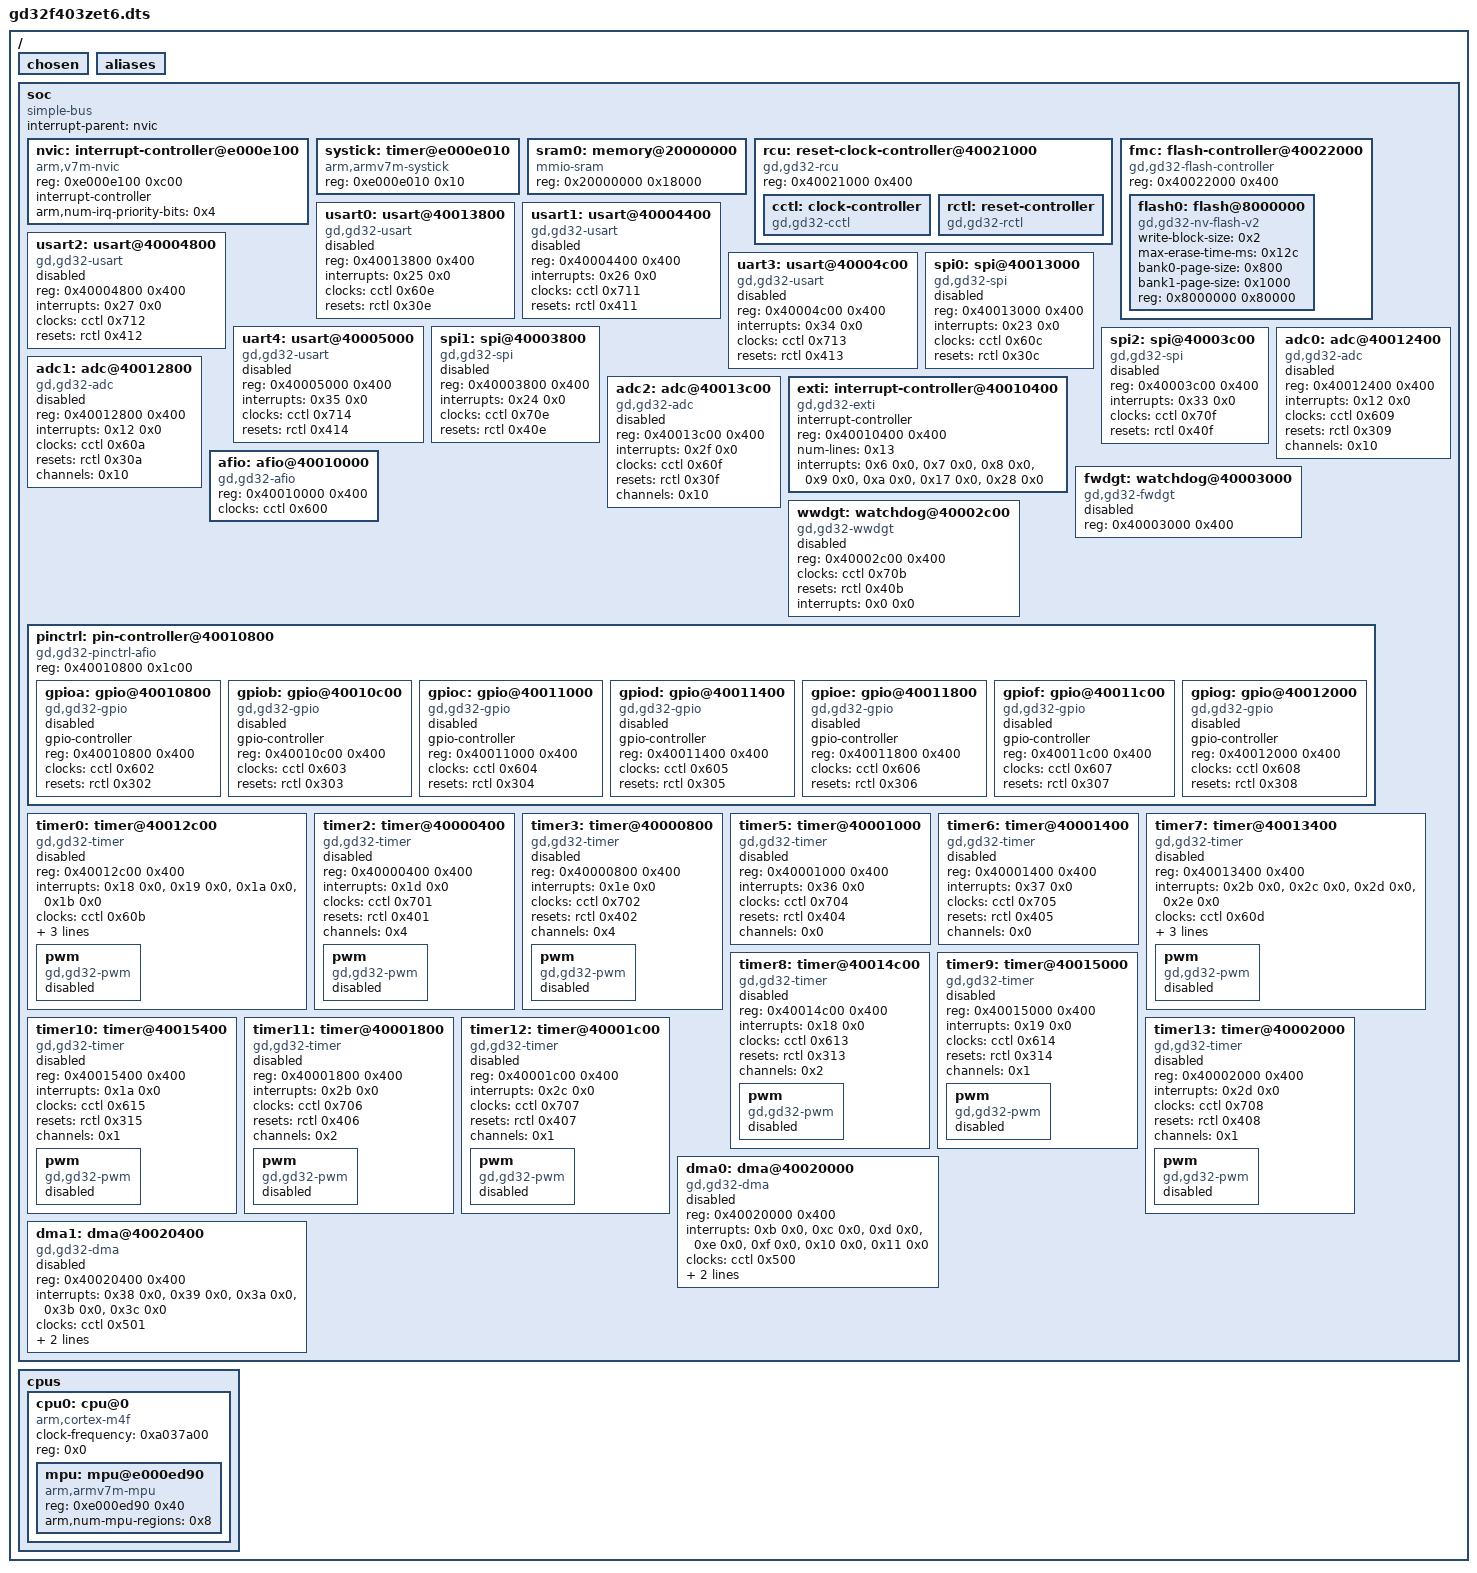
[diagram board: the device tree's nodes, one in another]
/dts-v1/;

/ {
	#address-cells = < 0x1 >;
	#size-cells = < 0x1 >;
	chosen {
	};
	aliases {
	};
	soc {
		#address-cells = < 0x1 >;
		#size-cells = < 0x1 >;
		compatible = "simple-bus";
		interrupt-parent = < &nvic >;
		ranges;
		nvic: interrupt-controller@e000e100 {
			#address-cells = < 0x1 >;
			compatible = "arm,v7m-nvic";
			reg = < 0xe000e100 0xc00 >;
			interrupt-controller;
			#interrupt-cells = < 0x2 >;
			arm,num-irq-priority-bits = < 0x4 >;
			phandle = < 0x1 >;
		};
		systick: timer@e000e010 {
			compatible = "arm,armv7m-systick";
			reg = < 0xe000e010 0x10 >;
		};
		sram0: memory@20000000 {
			compatible = "mmio-sram";
			reg = < 0x20000000 0x18000 >;
		};
		rcu: reset-clock-controller@40021000 {
			compatible = "gd,gd32-rcu";
			reg = < 0x40021000 0x400 >;
			status = "okay";
			cctl: clock-controller {
				compatible = "gd,gd32-cctl";
				#clock-cells = < 0x1 >;
				status = "okay";
				phandle = < 0x2 >;
			};
			rctl: reset-controller {
				compatible = "gd,gd32-rctl";
				#reset-cells = < 0x1 >;
				status = "okay";
				phandle = < 0x3 >;
			};
		};
		fmc: flash-controller@40022000 {
			compatible = "gd,gd32-flash-controller";
			reg = < 0x40022000 0x400 >;
			#address-cells = < 0x1 >;
			#size-cells = < 0x1 >;
			flash0: flash@8000000 {
				compatible = "gd,gd32-nv-flash-v2", "soc-nv-flash";
				write-block-size = < 0x2 >;
				max-erase-time-ms = < 0x12c >;
				bank0-page-size = < 0x800 >;
				bank1-page-size = < 0x1000 >;
				reg = < 0x8000000 0x80000 >;
			};
		};
		usart0: usart@40013800 {
			compatible = "gd,gd32-usart";
			reg = < 0x40013800 0x400 >;
			interrupts = < 0x25 0x0 >;
			clocks = < &cctl 0x60e >;
			resets = < &rctl 0x30e >;
			status = "disabled";
		};
		usart1: usart@40004400 {
			compatible = "gd,gd32-usart";
			reg = < 0x40004400 0x400 >;
			interrupts = < 0x26 0x0 >;
			clocks = < &cctl 0x711 >;
			resets = < &rctl 0x411 >;
			status = "disabled";
		};
		usart2: usart@40004800 {
			compatible = "gd,gd32-usart";
			reg = < 0x40004800 0x400 >;
			interrupts = < 0x27 0x0 >;
			clocks = < &cctl 0x712 >;
			resets = < &rctl 0x412 >;
			status = "disabled";
		};
		uart3: usart@40004c00 {
			compatible = "gd,gd32-usart";
			reg = < 0x40004c00 0x400 >;
			interrupts = < 0x34 0x0 >;
			clocks = < &cctl 0x713 >;
			resets = < &rctl 0x413 >;
			status = "disabled";
		};
		uart4: usart@40005000 {
			compatible = "gd,gd32-usart";
			reg = < 0x40005000 0x400 >;
			interrupts = < 0x35 0x0 >;
			clocks = < &cctl 0x714 >;
			resets = < &rctl 0x414 >;
			status = "disabled";
		};
		spi0: spi@40013000 {
			compatible = "gd,gd32-spi";
			reg = < 0x40013000 0x400 >;
			interrupts = < 0x23 0x0 >;
			clocks = < &cctl 0x60c >;
			resets = < &rctl 0x30c >;
			status = "disabled";
			#address-cells = < 0x1 >;
			#size-cells = < 0x0 >;
		};
		spi1: spi@40003800 {
			compatible = "gd,gd32-spi";
			reg = < 0x40003800 0x400 >;
			interrupts = < 0x24 0x0 >;
			clocks = < &cctl 0x70e >;
			resets = < &rctl 0x40e >;
			status = "disabled";
			#address-cells = < 0x1 >;
			#size-cells = < 0x0 >;
		};
		spi2: spi@40003c00 {
			compatible = "gd,gd32-spi";
			reg = < 0x40003c00 0x400 >;
			interrupts = < 0x33 0x0 >;
			clocks = < &cctl 0x70f >;
			resets = < &rctl 0x40f >;
			status = "disabled";
			#address-cells = < 0x1 >;
			#size-cells = < 0x0 >;
		};
		adc0: adc@40012400 {
			compatible = "gd,gd32-adc";
			reg = < 0x40012400 0x400 >;
			interrupts = < 0x12 0x0 >;
			clocks = < &cctl 0x609 >;
			resets = < &rctl 0x309 >;
			channels = < 0x10 >;
			status = "disabled";
			#io-channel-cells = < 0x1 >;
		};
		adc1: adc@40012800 {
			compatible = "gd,gd32-adc";
			reg = < 0x40012800 0x400 >;
			interrupts = < 0x12 0x0 >;
			clocks = < &cctl 0x60a >;
			resets = < &rctl 0x30a >;
			channels = < 0x10 >;
			status = "disabled";
			#io-channel-cells = < 0x1 >;
		};
		adc2: adc@40013c00 {
			compatible = "gd,gd32-adc";
			reg = < 0x40013c00 0x400 >;
			interrupts = < 0x2f 0x0 >;
			clocks = < &cctl 0x60f >;
			resets = < &rctl 0x30f >;
			channels = < 0x10 >;
			status = "disabled";
			#io-channel-cells = < 0x1 >;
		};
		exti: interrupt-controller@40010400 {
			compatible = "gd,gd32-exti";
			interrupt-controller;
			#interrupt-cells = < 0x1 >;
			reg = < 0x40010400 0x400 >;
			num-lines = < 0x13 >;
			interrupts = < 0x6 0x0 >, < 0x7 0x0 >, < 0x8 0x0 >, < 0x9 0x0 >, < 0xa 0x0 >, < 0x17 0x0 >, < 0x28 0x0 >;
			interrupt-names = "line0", "line1", "line2", "line3", "line4", "line5-9", "line10-15";
			status = "okay";
		};
		afio: afio@40010000 {
			compatible = "gd,gd32-afio";
			reg = < 0x40010000 0x400 >;
			clocks = < &cctl 0x600 >;
			status = "okay";
		};
		fwdgt: watchdog@40003000 {
			compatible = "gd,gd32-fwdgt";
			reg = < 0x40003000 0x400 >;
			status = "disabled";
		};
		wwdgt: watchdog@40002c00 {
			compatible = "gd,gd32-wwdgt";
			reg = < 0x40002c00 0x400 >;
			clocks = < &cctl 0x70b >;
			resets = < &rctl 0x40b >;
			interrupts = < 0x0 0x0 >;
			status = "disabled";
		};
		pinctrl: pin-controller@40010800 {
			compatible = "gd,gd32-pinctrl-afio";
			reg = < 0x40010800 0x1c00 >;
			#address-cells = < 0x1 >;
			#size-cells = < 0x1 >;
			status = "okay";
			gpioa: gpio@40010800 {
				compatible = "gd,gd32-gpio";
				gpio-controller;
				#gpio-cells = < 0x2 >;
				reg = < 0x40010800 0x400 >;
				clocks = < &cctl 0x602 >;
				resets = < &rctl 0x302 >;
				status = "disabled";
			};
			gpiob: gpio@40010c00 {
				compatible = "gd,gd32-gpio";
				gpio-controller;
				#gpio-cells = < 0x2 >;
				reg = < 0x40010c00 0x400 >;
				clocks = < &cctl 0x603 >;
				resets = < &rctl 0x303 >;
				status = "disabled";
			};
			gpioc: gpio@40011000 {
				compatible = "gd,gd32-gpio";
				gpio-controller;
				#gpio-cells = < 0x2 >;
				reg = < 0x40011000 0x400 >;
				clocks = < &cctl 0x604 >;
				resets = < &rctl 0x304 >;
				status = "disabled";
			};
			gpiod: gpio@40011400 {
				compatible = "gd,gd32-gpio";
				gpio-controller;
				#gpio-cells = < 0x2 >;
				reg = < 0x40011400 0x400 >;
				clocks = < &cctl 0x605 >;
				resets = < &rctl 0x305 >;
				status = "disabled";
			};
			gpioe: gpio@40011800 {
				compatible = "gd,gd32-gpio";
				gpio-controller;
				#gpio-cells = < 0x2 >;
				reg = < 0x40011800 0x400 >;
				clocks = < &cctl 0x606 >;
				resets = < &rctl 0x306 >;
				status = "disabled";
			};
			gpiof: gpio@40011c00 {
				compatible = "gd,gd32-gpio";
				gpio-controller;
				#gpio-cells = < 0x2 >;
				reg = < 0x40011c00 0x400 >;
				clocks = < &cctl 0x607 >;
				resets = < &rctl 0x307 >;
				status = "disabled";
			};
			gpiog: gpio@40012000 {
				compatible = "gd,gd32-gpio";
				gpio-controller;
				#gpio-cells = < 0x2 >;
				reg = < 0x40012000 0x400 >;
				clocks = < &cctl 0x608 >;
				resets = < &rctl 0x308 >;
				status = "disabled";
			};
		};
		timer0: timer@40012c00 {
			compatible = "gd,gd32-timer";
			reg = < 0x40012c00 0x400 >;
			interrupts = < 0x18 0x0 >, < 0x19 0x0 >, < 0x1a 0x0 >, < 0x1b 0x0 >;
			interrupt-names = "brk", "up", "trgcom", "cc";
			clocks = < &cctl 0x60b >;
			resets = < &rctl 0x30b >;
			is-advanced;
			channels = < 0x4 >;
			status = "disabled";
			pwm {
				compatible = "gd,gd32-pwm";
				status = "disabled";
				#pwm-cells = < 0x3 >;
			};
		};
		timer2: timer@40000400 {
			compatible = "gd,gd32-timer";
			reg = < 0x40000400 0x400 >;
			interrupts = < 0x1d 0x0 >;
			interrupt-names = "global";
			clocks = < &cctl 0x701 >;
			resets = < &rctl 0x401 >;
			channels = < 0x4 >;
			status = "disabled";
			pwm {
				compatible = "gd,gd32-pwm";
				status = "disabled";
				#pwm-cells = < 0x3 >;
			};
		};
		timer3: timer@40000800 {
			compatible = "gd,gd32-timer";
			reg = < 0x40000800 0x400 >;
			interrupts = < 0x1e 0x0 >;
			interrupt-names = "global";
			clocks = < &cctl 0x702 >;
			resets = < &rctl 0x402 >;
			channels = < 0x4 >;
			status = "disabled";
			pwm {
				compatible = "gd,gd32-pwm";
				status = "disabled";
				#pwm-cells = < 0x3 >;
			};
		};
		timer5: timer@40001000 {
			compatible = "gd,gd32-timer";
			reg = < 0x40001000 0x400 >;
			interrupts = < 0x36 0x0 >;
			interrupt-names = "global";
			clocks = < &cctl 0x704 >;
			resets = < &rctl 0x404 >;
			channels = < 0x0 >;
			status = "disabled";
		};
		timer6: timer@40001400 {
			compatible = "gd,gd32-timer";
			reg = < 0x40001400 0x400 >;
			interrupts = < 0x37 0x0 >;
			interrupt-names = "global";
			clocks = < &cctl 0x705 >;
			resets = < &rctl 0x405 >;
			channels = < 0x0 >;
			status = "disabled";
		};
		timer7: timer@40013400 {
			compatible = "gd,gd32-timer";
			reg = < 0x40013400 0x400 >;
			interrupts = < 0x2b 0x0 >, < 0x2c 0x0 >, < 0x2d 0x0 >, < 0x2e 0x0 >;
			interrupt-names = "brk", "up", "trgcom", "cc";
			clocks = < &cctl 0x60d >;
			resets = < &rctl 0x30d >;
			is-advanced;
			channels = < 0x4 >;
			status = "disabled";
			pwm {
				compatible = "gd,gd32-pwm";
				status = "disabled";
				#pwm-cells = < 0x3 >;
			};
		};
		timer8: timer@40014c00 {
			compatible = "gd,gd32-timer";
			reg = < 0x40014c00 0x400 >;
			interrupts = < 0x18 0x0 >;
			interrupt-names = "global";
			clocks = < &cctl 0x613 >;
			resets = < &rctl 0x313 >;
			channels = < 0x2 >;
			status = "disabled";
			pwm {
				compatible = "gd,gd32-pwm";
				status = "disabled";
				#pwm-cells = < 0x3 >;
			};
		};
		timer9: timer@40015000 {
			compatible = "gd,gd32-timer";
			reg = < 0x40015000 0x400 >;
			interrupts = < 0x19 0x0 >;
			interrupt-names = "global";
			clocks = < &cctl 0x614 >;
			resets = < &rctl 0x314 >;
			channels = < 0x1 >;
			status = "disabled";
			pwm {
				compatible = "gd,gd32-pwm";
				status = "disabled";
				#pwm-cells = < 0x3 >;
			};
		};
		timer10: timer@40015400 {
			compatible = "gd,gd32-timer";
			reg = < 0x40015400 0x400 >;
			interrupts = < 0x1a 0x0 >;
			interrupt-names = "global";
			clocks = < &cctl 0x615 >;
			resets = < &rctl 0x315 >;
			channels = < 0x1 >;
			status = "disabled";
			pwm {
				compatible = "gd,gd32-pwm";
				status = "disabled";
				#pwm-cells = < 0x3 >;
			};
		};
		timer11: timer@40001800 {
			compatible = "gd,gd32-timer";
			reg = < 0x40001800 0x400 >;
			interrupts = < 0x2b 0x0 >;
			interrupt-names = "global";
			clocks = < &cctl 0x706 >;
			resets = < &rctl 0x406 >;
			channels = < 0x2 >;
			status = "disabled";
			pwm {
				compatible = "gd,gd32-pwm";
				status = "disabled";
				#pwm-cells = < 0x3 >;
			};
		};
		timer12: timer@40001c00 {
			compatible = "gd,gd32-timer";
			reg = < 0x40001c00 0x400 >;
			interrupts = < 0x2c 0x0 >;
			interrupt-names = "global";
			clocks = < &cctl 0x707 >;
			resets = < &rctl 0x407 >;
			channels = < 0x1 >;
			status = "disabled";
			pwm {
				compatible = "gd,gd32-pwm";
				status = "disabled";
				#pwm-cells = < 0x3 >;
			};
		};
		timer13: timer@40002000 {
			compatible = "gd,gd32-timer";
			reg = < 0x40002000 0x400 >;
			interrupts = < 0x2d 0x0 >;
			interrupt-names = "global";
			clocks = < &cctl 0x708 >;
			resets = < &rctl 0x408 >;
			channels = < 0x1 >;
			status = "disabled";
			pwm {
				compatible = "gd,gd32-pwm";
				status = "disabled";
				#pwm-cells = < 0x3 >;
			};
		};
		dma0: dma@40020000 {
			compatible = "gd,gd32-dma";
			reg = < 0x40020000 0x400 >;
			interrupts = < 0xb 0x0 >, < 0xc 0x0 >, < 0xd 0x0 >, < 0xe 0x0 >, < 0xf 0x0 >, < 0x10 0x0 >, < 0x11 0x0 >;
			clocks = < &cctl 0x500 >;
			dma-channels = < 0x7 >;
			gd,mem2mem;
			#dma-cells = < 0x2 >;
			status = "disabled";
		};
		dma1: dma@40020400 {
			compatible = "gd,gd32-dma";
			reg = < 0x40020400 0x400 >;
			interrupts = < 0x38 0x0 >, < 0x39 0x0 >, < 0x3a 0x0 >, < 0x3b 0x0 >, < 0x3c 0x0 >;
			clocks = < &cctl 0x501 >;
			dma-channels = < 0x5 >;
			gd,mem2mem;
			#dma-cells = < 0x2 >;
			status = "disabled";
		};
	};
	cpus {
		#address-cells = < 0x1 >;
		#size-cells = < 0x0 >;
		cpu0: cpu@0 {
			compatible = "arm,cortex-m4f";
			clock-frequency = < 0xa037a00 >;
			reg = < 0x0 >;
			#address-cells = < 0x1 >;
			#size-cells = < 0x1 >;
			mpu: mpu@e000ed90 {
				compatible = "arm,armv7m-mpu";
				reg = < 0xe000ed90 0x40 >;
				arm,num-mpu-regions = < 0x8 >;
			};
		};
	};
};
